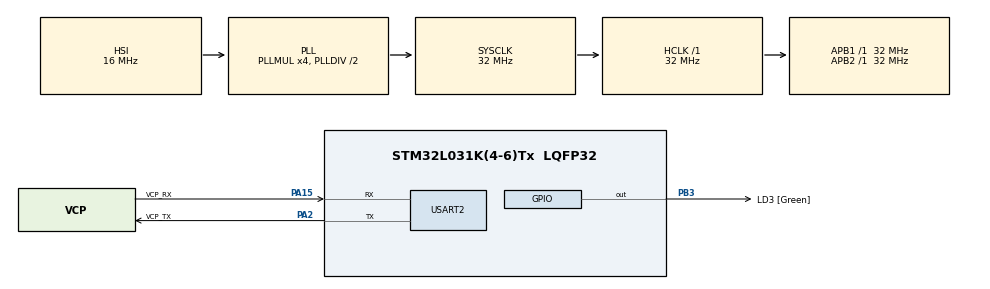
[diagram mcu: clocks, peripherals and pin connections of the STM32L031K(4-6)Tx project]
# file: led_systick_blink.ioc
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Mcu.Family=STM32L0
Mcu.Name=STM32L031K(4-6)Tx
Mcu.Package=LQFP32
PA13.GPIO_Label=TMS
PA13.Mode=Serial_Wire
PA13.Signal=SYS_SWDIO
PA14.GPIO_Label=TCK
PA14.Mode=Serial_Wire
PA14.Signal=SYS_SWCLK
PA15.GPIO_Label=VCP_RX
PA15.Mode=Asynchronous
PA15.Signal=USART2_RX
PA2.GPIO_Label=VCP_TX
PA2.Mode=Asynchronous
PA2.Signal=USART2_TX
PB3.GPIO_Label=LD3 [Green]
PB3.Signal=GPIO_Output
PC14-OSC32_IN.Mode=LSE-External-Oscillator
PC14-OSC32_IN.Signal=RCC_OSC32_IN
PC15-OSC32_OUT.Mode=LSE-External-Oscillator
PC15-OSC32_OUT.Signal=RCC_OSC32_OUT
ProjectManager.HeapSize=0x200
ProjectManager.StackSize=0x400
ProjectManager.TargetToolchain=MDK-ARM V5
RCC.AHBFreq_Value=32000000
RCC.APB1Freq_Value=32000000
RCC.APB1TimFreq_Value=32000000
RCC.APB2Freq_Value=32000000
RCC.APB2TimFreq_Value=32000000
RCC.HCLKFreq_Value=32000000
RCC.HSE_VALUE=8000000
RCC.HSI16_VALUE=16000000
RCC.HSI48_VALUE=48000000
RCC.HSI_VALUE=16000000
RCC.MSI_VALUE=2097000
RCC.PLLMUL=RCC_PLLMUL_4
RCC.SYSCLKFreq_VALUE=32000000
RCC.SYSCLKSource=RCC_SYSCLKSOURCE_PLLCLK
RCC.VCOOutputFreq_Value=64000000
USART2.VirtualMode-Asynchronous=VM_ASYNC
board=NUCLEO-L031K6

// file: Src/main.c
/* USER CODE BEGIN Header */
/**
  ******************************************************************************
  * @file           : main.c
  * @brief          : Main program body
  ******************************************************************************
  * @attention
  *
  * <h2><center>&copy; Copyright (c) 2019 STMicroelectronics.
  * All rights reserved.</center></h2>
  *
  * This software component is licensed by ST under BSD 3-Clause license,
  * the "License"; You may not use this file except in compliance with the
  * License. You may obtain a copy of the License at:
  *                        opensource.org/licenses/BSD-3-Clause
  *
  ******************************************************************************
  */
/* USER CODE END Header */

#include "main.h"

UART_HandleTypeDef huart2;

/* USER CODE BEGIN PV */

//uint32_t delay_temp, delay_count;
	uint8_t flag_sys;
	uint16_t delay_ms;
/* USER CODE END PV */

void SystemClock_Config(void);
static void MX_GPIO_Init(void);
static void MX_USART2_UART_Init(void);

int main(void)
{
  /* USER CODE BEGIN 1 */
	//delay_temp = HAL_GetTick();
	//delay_count = 500;
  /* USER CODE END 1 */

  /* MCU Configuration--------------------------------------------------------*/

  /* Reset of all peripherals, Initializes the Flash interface and the Systick. */
  HAL_Init();

  /* Configure the system clock */
  SystemClock_Config();

  /* Initialize all configured peripherals */
  MX_GPIO_Init();
  MX_USART2_UART_Init();

  /* Infinite loop */
  while (1)
  {
		//if(HAL_GetTick() - delay_temp > delay_count){
			//HAL_GPIO_TogglePin(GPIOB, GPIO_PIN_3);
			//delay_temp = HAL_GetTick();
		//}
		if(!delay_ms){
			HAL_GPIO_TogglePin(GPIOB, GPIO_PIN_3);
			delay_ms = 500;
		}
		if(flag_sys){
			flag_sys = 0;
			if(delay_ms>0){
				delay_ms--;
			}
		}

  }
}

void SystemClock_Config(void)
{
  RCC_OscInitTypeDef RCC_OscInitStruct = {0};
  RCC_ClkInitTypeDef RCC_ClkInitStruct = {0};
  RCC_PeriphCLKInitTypeDef PeriphClkInit = {0};

  /** Configure the main internal regulator output voltage
  */
  __HAL_PWR_VOLTAGESCALING_CONFIG(PWR_REGULATOR_VOLTAGE_SCALE1);
  /** Initializes the CPU, AHB and APB busses clocks
  */
  RCC_OscInitStruct.OscillatorType = RCC_OSCILLATORTYPE_HSI;
  RCC_OscInitStruct.HSIState = RCC_HSI_ON;
  RCC_OscInitStruct.HSICalibrationValue = RCC_HSICALIBRATION_DEFAULT;
  RCC_OscInitStruct.PLL.PLLState = RCC_PLL_ON;
  RCC_OscInitStruct.PLL.PLLSource = RCC_PLLSOURCE_HSI;
  RCC_OscInitStruct.PLL.PLLMUL = RCC_PLLMUL_4;
  RCC_OscInitStruct.PLL.PLLDIV = RCC_PLLDIV_2;
  if (HAL_RCC_OscConfig(&RCC_OscInitStruct) != HAL_OK)
  {
    Error_Handler();
  }
  /** Initializes the CPU, AHB and APB busses clocks
  */
  RCC_ClkInitStruct.ClockType = RCC_CLOCKTYPE_HCLK|RCC_CLOCKTYPE_SYSCLK
                              |RCC_CLOCKTYPE_PCLK1|RCC_CLOCKTYPE_PCLK2;
  RCC_ClkInitStruct.SYSCLKSource = RCC_SYSCLKSOURCE_PLLCLK;
  RCC_ClkInitStruct.AHBCLKDivider = RCC_SYSCLK_DIV1;
  RCC_ClkInitStruct.APB1CLKDivider = RCC_HCLK_DIV1;
  RCC_ClkInitStruct.APB2CLKDivider = RCC_HCLK_DIV1;

  if (HAL_RCC_ClockConfig(&RCC_ClkInitStruct, FLASH_LATENCY_1) != HAL_OK)
  {
    Error_Handler();
  }
  PeriphClkInit.PeriphClockSelection = RCC_PERIPHCLK_USART2;
  PeriphClkInit.Usart2ClockSelection = RCC_USART2CLKSOURCE_PCLK1;
  if (HAL_RCCEx_PeriphCLKConfig(&PeriphClkInit) != HAL_OK)
  {
    Error_Handler();
  }
}

static void MX_USART2_UART_Init(void)
{

  huart2.Instance = USART2;
  huart2.Init.BaudRate = 115200;
  huart2.Init.WordLength = UART_WORDLENGTH_8B;
  huart2.Init.StopBits = UART_STOPBITS_1;
  huart2.Init.Parity = UART_PARITY_NONE;
  huart2.Init.Mode = UART_MODE_TX_RX;
  huart2.Init.HwFlowCtl = UART_HWCONTROL_NONE;
  huart2.Init.OverSampling = UART_OVERSAMPLING_16;
  huart2.Init.OneBitSampling = UART_ONE_BIT_SAMPLE_DISABLE;
  huart2.AdvancedInit.AdvFeatureInit = UART_ADVFEATURE_NO_INIT;
  if (HAL_UART_Init(&huart2) != HAL_OK)
  {
    Error_Handler();
  }

}

static void MX_GPIO_Init(void)
{
  GPIO_InitTypeDef GPIO_InitStruct = {0};

  /* GPIO Ports Clock Enable */
  __HAL_RCC_GPIOC_CLK_ENABLE();
  __HAL_RCC_GPIOA_CLK_ENABLE();
  __HAL_RCC_GPIOB_CLK_ENABLE();

  /*Configure GPIO pin Output Level */
  HAL_GPIO_WritePin(LD3_GPIO_Port, LD3_Pin, GPIO_PIN_RESET);

  /*Configure GPIO pin : LD3_Pin */
  GPIO_InitStruct.Pin = LD3_Pin;
  GPIO_InitStruct.Mode = GPIO_MODE_OUTPUT_PP;
  GPIO_InitStruct.Pull = GPIO_NOPULL;
  GPIO_InitStruct.Speed = GPIO_SPEED_FREQ_LOW;
  HAL_GPIO_Init(LD3_GPIO_Port, &GPIO_InitStruct);

}

void Error_Handler(void)
{
}

/************************ (C) COPYRIGHT STMicroelectronics *****END OF FILE****/
